# CY8C5868LTI_LP039 register map
File version: 0.1
CY8C58LP
Registers are 8-bit, read-write, no defined reset value unless marked. A register's access mark holds for its fields unless they carry their own. Offsets are from the block's base; lines under a group give offsets from that group; [hi:lo] are bit positions; {n}, {i} and the like mark numbered series; 'fields as' and 'values as' point back to an identical list; <NAME> marks a mode.

## Memory map
0x00000000 servoPWM
0x00000000 UART

## servoPWM
Base 0x00000000
0x40006524 servoPWM_COMPARE_Reg_ — UDB.D0 - Assigned Compare Value
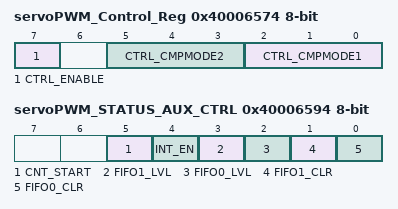
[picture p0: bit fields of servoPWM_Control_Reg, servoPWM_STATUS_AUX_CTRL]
0x40006574 servoPWM_Control_Reg — UDB Control Register - Assigned Control Register Value
  [7] CTRL_ENABLE — Enable the PWM
  [5:3] CTRL_CMPMODE2 — Compare mode 2
  [2:0] CTRL_CMPMODE1 — Compare mode 1
0x40006594 servoPWM_STATUS_AUX_CTRL — UDB Auxilliary Control Register
  [5] CNT_START — FIFO0 clear
    0=E_CNT_START0 (Disable counter); 1=E_CNT_START1 (Enable counter)
  [4] INT_EN
    0=E_INT_EN0 (Interrupt disabled); 1=E_INT_EN1 (Interrupt enabled)
  [3] FIFO1_LVL — FIFO level
    0=E_FIFO_LVL_0 (FIFO LVL: input mode: FIFO not full; output mode: FIFO not empty); 1=E_FIFO_LVL_1 (FIFO LVL: input mode: FIFO at least 1/2 empty; output mode: FIFO at least 1/2 full)
  [2] FIFO0_LVL — FIFO level
    values as FIFO1_LVL
  [1] FIFO1_CLR — FIFO1 clear
    0=E_FIFO_CLR_0 (Normal FIFO operation); 1=E_FIFO_CLR_1 (Clear FIFO state)
  [0] FIFO0_CLR — FIFO0 clear
    values as FIFO1_CLR

## UART
Base 0x00000000
0x40006446 TX_UART_TX_DATA — TX Data Register
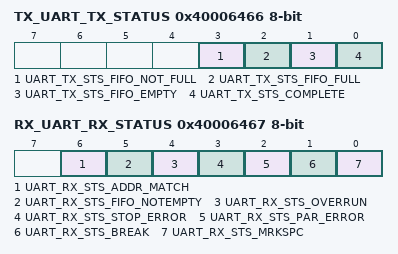
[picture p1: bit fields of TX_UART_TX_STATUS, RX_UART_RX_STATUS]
0x40006466 TX_UART_TX_STATUS — TX status register
  [3] UART_TX_STS_FIFO_NOT_FULL ro, [2] UART_TX_STS_FIFO_FULL ro, [1] UART_TX_STS_FIFO_EMPTY ro, [0] UART_TX_STS_COMPLETE ro
0x40006467 RX_UART_RX_STATUS — RX status register
  [6] UART_RX_STS_ADDR_MATCH ro, [5] UART_RX_STS_FIFO_NOTEMPTY ro, [4] UART_RX_STS_OVERRUN ro, [3] UART_RX_STS_STOP_ERROR ro, [2] UART_RX_STS_PAR_ERROR ro, [1] UART_RX_STS_BREAK ro, [0] UART_RX_STS_MRKSPC ro
0x40006525 RX_UART_RX_ADDRESS1 — RX Address1 Register
0x40006535 RX_UART_RX_ADDRESS2 — RX Address2 Register
0x40006545 RX_UART_RX_DATA — RX Data Register
